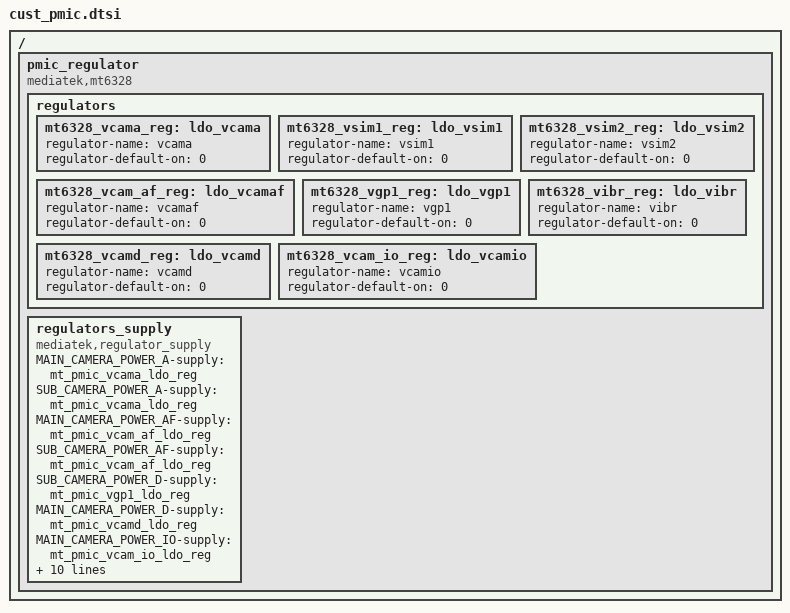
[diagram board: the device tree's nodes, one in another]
/*
 * Generated by MTK SP DrvGen Version 03.13.6 for MT6753. Copyright MediaTek Inc. (C) 2013.
 * Thu Aug 13 20:08:34 2015
 * Do Not Modify the File.
 */

/*************************
 * PMIC DTSI File
*************************/

/ {
	pmic_regulator {
		compatible = "mediatek,mt6328";
		/*reg = <0x01>*/
		regulators {
			mt6328_vcama_reg: ldo_vcama {
				regulator-name = "vcama";
				regulator-default-on = <0>; /* 0:skip, 1: off, 2:on */
			};
			mt6328_vsim1_reg: ldo_vsim1 {
				regulator-name = "vsim1";
				regulator-default-on = <0>; /* 0:skip, 1: off, 2:on */
			};
			mt6328_vsim2_reg: ldo_vsim2 {
				regulator-name = "vsim2";
				regulator-default-on = <0>; /* 0:skip, 1: off, 2:on */
			};
			mt6328_vcam_af_reg: ldo_vcamaf {
				regulator-name = "vcamaf";
				regulator-default-on = <0>; /* 0:skip, 1: off, 2:on */
			};
			mt6328_vgp1_reg: ldo_vgp1 {
				regulator-name = "vgp1";
				regulator-default-on = <0>; /* 0:skip, 1: off, 2:on */
			};
			mt6328_vibr_reg: ldo_vibr {
				regulator-name = "vibr";
				regulator-default-on = <0>; /* 0:skip, 1: off, 2:on */
			};
			mt6328_vcamd_reg: ldo_vcamd {
				regulator-name = "vcamd";
				regulator-default-on = <0>; /* 0:skip, 1: off, 2:on */
			};
			mt6328_vcam_io_reg: ldo_vcamio {
				regulator-name = "vcamio";
				regulator-default-on = <0>; /* 0:skip, 1: off, 2:on */
			};
		};

		regulators_supply {
			compatible = "mediatek,regulator_supply";
			MAIN_CAMERA_POWER_A-supply = <&mt_pmic_vcama_ldo_reg>;
			SUB_CAMERA_POWER_A-supply = <&mt_pmic_vcama_ldo_reg>;
			MAIN_CAMERA_POWER_AF-supply = <&mt_pmic_vcam_af_ldo_reg>;
			SUB_CAMERA_POWER_AF-supply = <&mt_pmic_vcam_af_ldo_reg>;
			SUB_CAMERA_POWER_D-supply = <&mt_pmic_vgp1_ldo_reg>;
			MAIN_CAMERA_POWER_D-supply = <&mt_pmic_vcamd_ldo_reg>;
			MAIN_CAMERA_POWER_IO-supply = <&mt_pmic_vcam_io_ldo_reg>;
			SUB_CAMERA_POWER_IO-supply = <&mt_pmic_vcam_io_ldo_reg>;
			MAIN_CAMERA_POWER_A = "VCAMA";
			SUB_CAMERA_POWER_A = "VCAMA";
			MAIN_CAMERA_POWER_AF = "VCAMAF";
			SUB_CAMERA_POWER_AF = "VCAMAF";
			SUB_CAMERA_POWER_D = "VGP1";
			MAIN_CAMERA_POWER_D = "VCAMD";
			MAIN_CAMERA_POWER_IO = "VCAMIO";
			SUB_CAMERA_POWER_IO = "VCAMIO";
		};
	};
};
